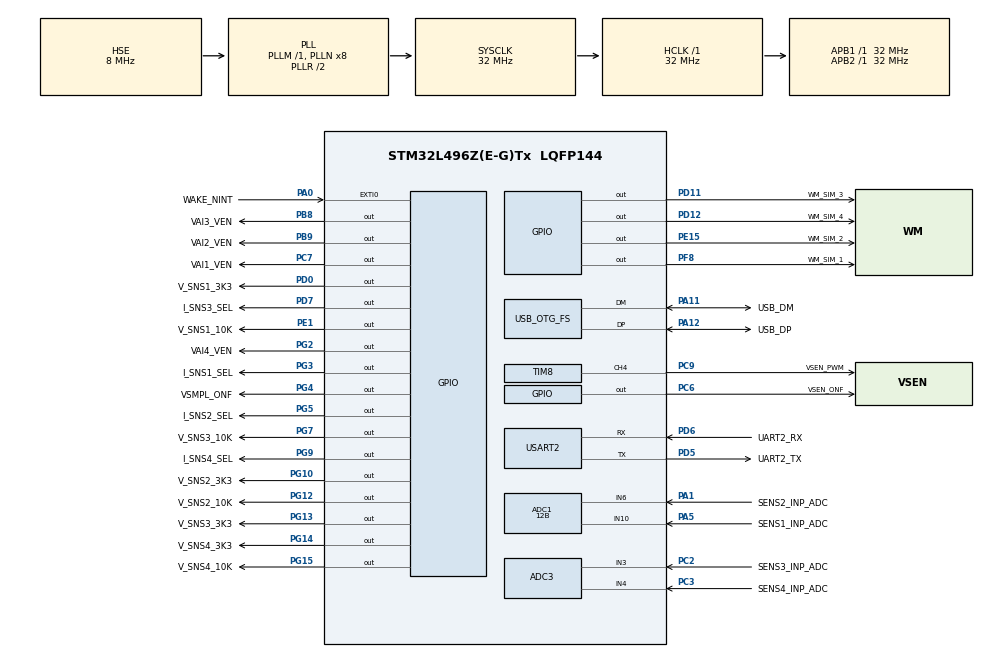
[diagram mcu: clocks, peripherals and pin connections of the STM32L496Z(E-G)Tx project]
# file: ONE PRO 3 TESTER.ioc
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ADC1.Channel-1\#ChannelRegularConversion=ADC_CHANNEL_6
ADC1.Channel-10\#ChannelRegularConversion=ADC_CHANNEL_6
ADC1.Channel-11\#ChannelRegularConversion=ADC_CHANNEL_6
ADC1.Channel-12\#ChannelRegularConversion=ADC_CHANNEL_6
ADC1.Channel-13\#ChannelRegularConversion=ADC_CHANNEL_6
ADC1.Channel-14\#ChannelRegularConversion=ADC_CHANNEL_6
ADC1.Channel-15\#ChannelRegularConversion=ADC_CHANNEL_6
ADC1.Channel-16\#ChannelRegularConversion=ADC_CHANNEL_6
ADC1.Channel-2\#ChannelRegularConversion=ADC_CHANNEL_6
ADC1.Channel-3\#ChannelRegularConversion=ADC_CHANNEL_6
ADC1.Channel-4\#ChannelRegularConversion=ADC_CHANNEL_6
ADC1.Channel-5\#ChannelRegularConversion=ADC_CHANNEL_6
ADC1.Channel-6\#ChannelRegularConversion=ADC_CHANNEL_6
ADC1.Channel-7\#ChannelRegularConversion=ADC_CHANNEL_6
ADC1.Channel-8\#ChannelRegularConversion=ADC_CHANNEL_6
ADC1.Channel-9\#ChannelRegularConversion=ADC_CHANNEL_6
ADC1.ClockPrescaler=ADC_CLOCK_ASYNC_DIV128
ADC1.DMAContinuousRequestsForConfigFile-ADC_Settings=LIMITED
ADC1.DataAlign=ADC_DATAALIGN_RIGHT
ADC1.NbrOfConversion=16
ADC1.NbrOfConversionFlag=1
ADC1.OffsetNumber-1\#ChannelRegularConversion=ADC_OFFSET_NONE
ADC1.OffsetNumber-10\#ChannelRegularConversion=ADC_OFFSET_NONE
ADC1.OffsetNumber-11\#ChannelRegularConversion=ADC_OFFSET_NONE
ADC1.OffsetNumber-12\#ChannelRegularConversion=ADC_OFFSET_NONE
ADC1.OffsetNumber-13\#ChannelRegularConversion=ADC_OFFSET_NONE
ADC1.OffsetNumber-14\#ChannelRegularConversion=ADC_OFFSET_NONE
ADC1.OffsetNumber-15\#ChannelRegularConversion=ADC_OFFSET_NONE
ADC1.OffsetNumber-16\#ChannelRegularConversion=ADC_OFFSET_NONE
ADC1.OffsetNumber-2\#ChannelRegularConversion=ADC_OFFSET_NONE
ADC1.OffsetNumber-3\#ChannelRegularConversion=ADC_OFFSET_NONE
ADC1.OffsetNumber-4\#ChannelRegularConversion=ADC_OFFSET_NONE
ADC1.OffsetNumber-5\#ChannelRegularConversion=ADC_OFFSET_NONE
ADC1.OffsetNumber-6\#ChannelRegularConversion=ADC_OFFSET_NONE
ADC1.OffsetNumber-7\#ChannelRegularConversion=ADC_OFFSET_NONE
ADC1.OffsetNumber-8\#ChannelRegularConversion=ADC_OFFSET_NONE
ADC1.OffsetNumber-9\#ChannelRegularConversion=ADC_OFFSET_NONE
ADC1.Rank-1\#ChannelRegularConversion=1
ADC1.Rank-10\#ChannelRegularConversion=10
ADC1.Rank-11\#ChannelRegularConversion=11
ADC1.Rank-12\#ChannelRegularConversion=12
ADC1.Rank-13\#ChannelRegularConversion=13
ADC1.Rank-14\#ChannelRegularConversion=14
ADC1.Rank-15\#ChannelRegularConversion=15
ADC1.Rank-16\#ChannelRegularConversion=16
ADC1.Rank-2\#ChannelRegularConversion=2
ADC1.Rank-3\#ChannelRegularConversion=3
ADC1.Rank-4\#ChannelRegularConversion=4
ADC1.Rank-5\#ChannelRegularConversion=5
ADC1.Rank-6\#ChannelRegularConversion=6
ADC1.Rank-7\#ChannelRegularConversion=7
ADC1.Rank-8\#ChannelRegularConversion=8
ADC1.Rank-9\#ChannelRegularConversion=9
ADC1.Resolution=ADC_RESOLUTION_12B
ADC1.SamplingTime-1\#ChannelRegularConversion=ADC_SAMPLETIME_2CYCLES_5
ADC1.SamplingTime-10\#ChannelRegularConversion=ADC_SAMPLETIME_2CYCLES_5
ADC1.SamplingTime-11\#ChannelRegularConversion=ADC_SAMPLETIME_2CYCLES_5
ADC1.SamplingTime-12\#ChannelRegularConversion=ADC_SAMPLETIME_2CYCLES_5
ADC1.SamplingTime-13\#ChannelRegularConversion=ADC_SAMPLETIME_2CYCLES_5
ADC1.SamplingTime-14\#ChannelRegularConversion=ADC_SAMPLETIME_2CYCLES_5
ADC1.SamplingTime-15\#ChannelRegularConversion=ADC_SAMPLETIME_2CYCLES_5
ADC1.SamplingTime-16\#ChannelRegularConversion=ADC_SAMPLETIME_2CYCLES_5
ADC1.SamplingTime-2\#ChannelRegularConversion=ADC_SAMPLETIME_2CYCLES_5
ADC1.SamplingTime-3\#ChannelRegularConversion=ADC_SAMPLETIME_2CYCLES_5
ADC1.SamplingTime-4\#ChannelRegularConversion=ADC_SAMPLETIME_2CYCLES_5
ADC1.SamplingTime-5\#ChannelRegularConversion=ADC_SAMPLETIME_2CYCLES_5
ADC1.SamplingTime-6\#ChannelRegularConversion=ADC_SAMPLETIME_2CYCLES_5
ADC1.SamplingTime-7\#ChannelRegularConversion=ADC_SAMPLETIME_2CYCLES_5
ADC1.SamplingTime-8\#ChannelRegularConversion=ADC_SAMPLETIME_2CYCLES_5
ADC1.SamplingTime-9\#ChannelRegularConversion=ADC_SAMPLETIME_2CYCLES_5
ADC1.master=1
ADC3.Channel-10\#ChannelRegularConversion=ADC_CHANNEL_6
ADC3.Channel-11\#ChannelRegularConversion=ADC_CHANNEL_3
ADC3.Channel-12\#ChannelRegularConversion=ADC_CHANNEL_3
ADC3.Channel-13\#ChannelRegularConversion=ADC_CHANNEL_3
ADC3.Channel-14\#ChannelRegularConversion=ADC_CHANNEL_3
ADC3.Channel-15\#ChannelRegularConversion=ADC_CHANNEL_3
ADC3.Channel-16\#ChannelRegularConversion=ADC_CHANNEL_3
ADC3.Channel-17\#ChannelRegularConversion=ADC_CHANNEL_3
ADC3.Channel-18\#ChannelRegularConversion=ADC_CHANNEL_3
ADC3.Channel-19\#ChannelRegularConversion=ADC_CHANNEL_3
ADC3.Channel-20\#ChannelRegularConversion=ADC_CHANNEL_3
ADC3.Channel-21\#ChannelRegularConversion=ADC_CHANNEL_3
ADC3.Channel-22\#ChannelRegularConversion=ADC_CHANNEL_3
ADC3.Channel-23\#ChannelRegularConversion=ADC_CHANNEL_3
ADC3.Channel-24\#ChannelRegularConversion=ADC_CHANNEL_3
ADC3.Channel-25\#ChannelRegularConversion=ADC_CHANNEL_3
ADC3.ClockPrescaler=ADC_CLOCK_ASYNC_DIV128
ADC3.DataAlign=ADC_DATAALIGN_RIGHT
ADC3.NbrOfConversion=16
ADC3.NbrOfConversionFlag=1
ADC3.OffsetNumber-10\#ChannelRegularConversion=ADC_OFFSET_NONE
ADC3.OffsetNumber-11\#ChannelRegularConversion=ADC_OFFSET_NONE
ADC3.OffsetNumber-12\#ChannelRegularConversion=ADC_OFFSET_NONE
ADC3.OffsetNumber-13\#ChannelRegularConversion=ADC_OFFSET_NONE
ADC3.OffsetNumber-14\#ChannelRegularConversion=ADC_OFFSET_NONE
ADC3.OffsetNumber-15\#ChannelRegularConversion=ADC_OFFSET_NONE
ADC3.OffsetNumber-16\#ChannelRegularConversion=ADC_OFFSET_NONE
ADC3.OffsetNumber-17\#ChannelRegularConversion=ADC_OFFSET_NONE
ADC3.OffsetNumber-18\#ChannelRegularConversion=ADC_OFFSET_NONE
ADC3.OffsetNumber-19\#ChannelRegularConversion=ADC_OFFSET_NONE
ADC3.OffsetNumber-20\#ChannelRegularConversion=ADC_OFFSET_NONE
ADC3.OffsetNumber-21\#ChannelRegularConversion=ADC_OFFSET_NONE
ADC3.OffsetNumber-22\#ChannelRegularConversion=ADC_OFFSET_NONE
ADC3.OffsetNumber-23\#ChannelRegularConversion=ADC_OFFSET_NONE
ADC3.OffsetNumber-24\#ChannelRegularConversion=ADC_OFFSET_NONE
ADC3.OffsetNumber-25\#ChannelRegularConversion=ADC_OFFSET_NONE
ADC3.Rank-10\#ChannelRegularConversion=1
ADC3.Rank-11\#ChannelRegularConversion=2
ADC3.Rank-12\#ChannelRegularConversion=3
ADC3.Rank-13\#ChannelRegularConversion=4
ADC3.Rank-14\#ChannelRegularConversion=5
ADC3.Rank-15\#ChannelRegularConversion=6
ADC3.Rank-16\#ChannelRegularConversion=7
ADC3.Rank-17\#ChannelRegularConversion=8
ADC3.Rank-18\#ChannelRegularConversion=9
ADC3.Rank-19\#ChannelRegularConversion=10
ADC3.Rank-20\#ChannelRegularConversion=11
ADC3.Rank-21\#ChannelRegularConversion=12
ADC3.Rank-22\#ChannelRegularConversion=13
ADC3.Rank-23\#ChannelRegularConversion=14
ADC3.Rank-24\#ChannelRegularConversion=15
ADC3.Rank-25\#ChannelRegularConversion=16
ADC3.SamplingTime-10\#ChannelRegularConversion=ADC_SAMPLETIME_2CYCLES_5
ADC3.SamplingTime-11\#ChannelRegularConversion=ADC_SAMPLETIME_2CYCLES_5
ADC3.SamplingTime-12\#ChannelRegularConversion=ADC_SAMPLETIME_2CYCLES_5
ADC3.SamplingTime-13\#ChannelRegularConversion=ADC_SAMPLETIME_2CYCLES_5
ADC3.SamplingTime-14\#ChannelRegularConversion=ADC_SAMPLETIME_2CYCLES_5
ADC3.SamplingTime-15\#ChannelRegularConversion=ADC_SAMPLETIME_2CYCLES_5
ADC3.SamplingTime-16\#ChannelRegularConversion=ADC_SAMPLETIME_2CYCLES_5
ADC3.SamplingTime-17\#ChannelRegularConversion=ADC_SAMPLETIME_2CYCLES_5
ADC3.SamplingTime-18\#ChannelRegularConversion=ADC_SAMPLETIME_2CYCLES_5
ADC3.SamplingTime-19\#ChannelRegularConversion=ADC_SAMPLETIME_2CYCLES_5
ADC3.SamplingTime-20\#ChannelRegularConversion=ADC_SAMPLETIME_2CYCLES_5
ADC3.SamplingTime-21\#ChannelRegularConversion=ADC_SAMPLETIME_2CYCLES_5
ADC3.SamplingTime-22\#ChannelRegularConversion=ADC_SAMPLETIME_2CYCLES_5
ADC3.SamplingTime-23\#ChannelRegularConversion=ADC_SAMPLETIME_2CYCLES_5
ADC3.SamplingTime-24\#ChannelRegularConversion=ADC_SAMPLETIME_2CYCLES_5
ADC3.SamplingTime-25\#ChannelRegularConversion=ADC_SAMPLETIME_2CYCLES_5
Dma.Request0=USART2_RX
Dma.USART2_RX.0.Direction=DMA_PERIPH_TO_MEMORY
Dma.USART2_RX.0.Instance=DMA1_Channel6
Dma.USART2_RX.0.MemDataAlignment=DMA_MDATAALIGN_BYTE
Dma.USART2_RX.0.MemInc=DMA_MINC_ENABLE
Dma.USART2_RX.0.Mode=DMA_CIRCULAR
Dma.USART2_RX.0.PeriphDataAlignment=DMA_PDATAALIGN_BYTE
Dma.USART2_RX.0.PeriphInc=DMA_PINC_DISABLE
Dma.USART2_RX.0.Priority=DMA_PRIORITY_LOW
FREERTOS.Tasks01=defaultTask,24,512,StartDefaultTask,Default,NULL,Dynamic,NULL,NULL
FREERTOS.configMINIMAL_STACK_SIZE=512
FREERTOS.configTOTAL_HEAP_SIZE=16384
Mcu.Family=STM32L4
Mcu.Name=STM32L496Z(E-G)Tx
Mcu.Package=LQFP144
NVIC.DMA1_Channel6_IRQn=true\:5\:0\:false\:false\:true\:true\:false\:true\:true
NVIC.EXTI0_IRQn=true\:5\:0\:false\:false\:true\:true\:true\:true\:true
NVIC.OTG_FS_IRQn=true\:5\:0\:false\:false\:true\:true\:true\:true\:true
NVIC.PriorityGroup=NVIC_PRIORITYGROUP_4
NVIC.USART2_IRQn=true\:5\:0\:false\:false\:true\:true\:true\:true\:true
PA0.GPIO_Label=WAKE_NINT
PA0.Signal=GPXTI0
PA1.GPIO_Label=SENS2_INP_ADC
PA1.Signal=ADCx_IN6
PA11.GPIO_Label=USB_DM
PA11.Mode=Device_Only
PA11.Signal=USB_OTG_FS_DM
PA12.GPIO_Label=USB_DP
PA12.Mode=Device_Only
PA12.Signal=USB_OTG_FS_DP
PA13\ (JTMS/SWDIO).GPIO_Label=JTMS/SWDIO
PA13\ (JTMS/SWDIO).Mode=JTAG_5_pins
PA13\ (JTMS/SWDIO).Signal=SYS_JTMS-SWDIO
PA14\ (JTCK/SWCLK).Mode=JTAG_5_pins
PA14\ (JTCK/SWCLK).Signal=SYS_JTCK-SWCLK
PA15\ (JTDI).Mode=JTAG_5_pins
PA15\ (JTDI).Signal=SYS_JTDI
PA5.GPIO_Label=SENS1_INP_ADC
PA5.Signal=ADCx_IN10
PB3\ (JTDO/TRACESWO).GPIO_Label=JTDO/TRACESWO
PB3\ (JTDO/TRACESWO).Mode=JTAG_5_pins
PB3\ (JTDO/TRACESWO).Signal=SYS_JTDO-SWO
PB4\ (NJTRST).GPIO_Label=NJTRST
PB4\ (NJTRST).Mode=JTAG_5_pins
PB4\ (NJTRST).Signal=SYS_JTRST
PB8.GPIO_Label=VAI3_VEN
PB8.Signal=GPIO_Output
PB9.GPIO_Label=VAI2_VEN
PB9.Signal=GPIO_Output
PC14-OSC32_IN\ (PC14).Mode=LSE-External-Oscillator
PC14-OSC32_IN\ (PC14).Signal=RCC_OSC32_IN
PC15-OSC32_OUT\ (PC15).Mode=LSE-External-Oscillator
PC15-OSC32_OUT\ (PC15).Signal=RCC_OSC32_OUT
PC2.GPIO_Label=SENS3_INP_ADC
PC2.Signal=ADCx_IN3
PC3.GPIO_Label=SENS4_INP_ADC
PC3.Signal=ADCx_IN4
PC6.GPIO_Label=VSEN_ONF
PC6.Signal=GPIO_Output
PC7.GPIO_Label=VAI1_VEN
PC7.Signal=GPIO_Output
PC9.GPIO_Label=VSEN_PWM
PC9.Signal=S_TIM8_CH4
PD0.GPIO_Label=V_SNS1_3K3
PD0.Signal=GPIO_Output
PD11.GPIO_Label=WM_SIM_3
PD11.Signal=GPIO_Output
PD12.GPIO_Label=WM_SIM_4
PD12.Signal=GPIO_Output
PD5.GPIO_Label=UART2_TX
PD5.Mode=Asynchronous
PD5.Signal=USART2_TX
PD6.GPIO_Label=UART2_RX
PD6.GPIO_PuPd=GPIO_PULLUP
PD6.Mode=Asynchronous
PD6.Signal=USART2_RX
PD7.GPIO_Label=I_SNS3_SEL
PD7.Signal=GPIO_Output
PE1.GPIO_Label=V_SNS1_10K
PE1.Signal=GPIO_Output
PE15.GPIO_Label=WM_SIM_2
PE15.Signal=GPIO_Output
PF8.GPIO_Label=WM_SIM_1
PF8.Signal=GPIO_Output
PG10.GPIO_Label=V_SNS2_3K3
PG10.Signal=GPIO_Output
PG12.GPIO_Label=V_SNS2_10K
PG12.Signal=GPIO_Output
PG13.GPIO_Label=V_SNS3_3K3
PG13.Signal=GPIO_Output
PG14.GPIO_Label=V_SNS4_3K3
PG14.Signal=GPIO_Output
PG15.GPIO_Label=V_SNS4_10K
PG15.Signal=GPIO_Output
PG2.GPIO_Label=VAI4_VEN
PG2.Signal=GPIO_Output
PG3.GPIO_Label=I_SNS1_SEL
PG3.Signal=GPIO_Output
PG4.GPIO_Label=VSMPL_ONF
PG4.Signal=GPIO_Output
PG5.GPIO_Label=I_SNS2_SEL
PG5.Signal=GPIO_Output
PG7.GPIO_Label=V_SNS3_10K
PG7.Signal=GPIO_Output
PG9.GPIO_Label=I_SNS4_SEL
PG9.Signal=GPIO_Output
PH0-OSC_IN\ (PH0).Mode=HSE-External-Oscillator
PH0-OSC_IN\ (PH0).Signal=RCC_OSC_IN
PH1-OSC_OUT\ (PH1).Mode=HSE-External-Oscillator
PH1-OSC_OUT\ (PH1).Signal=RCC_OSC_OUT
ProjectManager.HeapSize=0x200
ProjectManager.StackSize=0x400
ProjectManager.TargetToolchain=STM32CubeIDE
RCC.ADCCLockSelection=RCC_ADCCLKSOURCE_PLLSAI2
RCC.ADCFreq_Value=8000000
RCC.AHBFreq_Value=32000000
RCC.APB1Freq_Value=32000000
RCC.APB1TimFreq_Value=32000000
RCC.APB2Freq_Value=32000000
RCC.APB2TimFreq_Value=32000000
RCC.CortexFreq_Value=32000000
RCC.FLatency-AdvancedSettings=FLASH_LATENCY_1
RCC.HCLKFreq_Value=32000000
RCC.HSE_VALUE=8000000
RCC.HSI48_VALUE=48000000
RCC.HSI_VALUE=16000000
RCC.LSE_Drive_Capability=RCC_LSEDRIVE_MEDIUMLOW
RCC.MSI_VALUE=4000000
RCC.PLLSAI1N=12
RCC.PLLSAI2R=RCC_PLLR_DIV8
RCC.PLLSourceVirtual=RCC_PLLSOURCE_HSE
RCC.RTCClockSelection=RCC_RTCCLKSOURCE_LSE
RCC.SYSCLKFreq_VALUE=32000000
RCC.SYSCLKSource=RCC_SYSCLKSOURCE_PLLCLK
RCC.USBFreq_Value=48000000
RCC.VCOOutputFreq_Value=64000000
RTC.Date=12
RTC.Month=RTC_MONTH_MAY
RTC.Seconds=1
RTC.StoreOperation=RTC_STOREOPERATION_SET
RTC.WeekDay=RTC_WEEKDAY_SUNDAY
RTC.Year=24
SH.ADCx_IN10.0=ADC1_IN10,IN10-Single-Ended
SH.ADCx_IN3.0=ADC3_IN3,IN3-Single-Ended
SH.ADCx_IN4.0=ADC3_IN4,IN4-Single-Ended
SH.ADCx_IN6.0=ADC1_IN6,IN6-Single-Ended
SH.S_TIM8_CH4.0=TIM8_CH4,PWM Generation4 CH4
TIM3.AutoReloadPreload=TIM_AUTORELOAD_PRELOAD_ENABLE
TIM3.ClockDivision=TIM_CLOCKDIVISION_DIV1
TIM3.Prescaler=0
TIM7.AutoReloadPreload=TIM_AUTORELOAD_PRELOAD_ENABLE
TIM8.AutoReloadPreload=TIM_AUTORELOAD_PRELOAD_ENABLE
TIM8.Channel-PWM\ Generation4\ CH4=TIM_CHANNEL_4
USART2.VirtualMode-Asynchronous=VM_ASYNC
USB_DEVICE.CLASS_NAME_FS=CDC
USB_DEVICE.VirtualMode=Cdc
USB_DEVICE.VirtualModeFS=Cdc_FS
USB_OTG_FS.VirtualMode=Device_Only
VP_FREERTOS_VS_CMSIS_V2.Mode=CMSIS_V2
VP_RTC_VS_RTC_Activate.Mode=RTC_Enabled
VP_RTC_VS_RTC_Calendar.Mode=RTC_Calendar
VP_TIM3_VS_ClockSourceINT.Mode=Internal
VP_TIM7_VS_ClockSourceINT.Mode=Enable_Timer
VP_TIM8_VS_ClockSourceINT.Mode=Internal
VP_USB_DEVICE_VS_USB_DEVICE_CDC_FS.Mode=CDC_FS
board=custom

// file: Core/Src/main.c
/* USER CODE BEGIN Header */
/**
  ******************************************************************************
  * @file           : main.c
  * @brief          : Main program body
  ******************************************************************************
  * @attention
  *
  * Copyright (c) 2026 STMicroelectronics.
  * All rights reserved.
  *
  * This software is licensed under terms that can be found in the LICENSE file
  * in the root directory of this software component.
  * If no LICENSE file comes with this software, it is provided AS-IS.
  *
  ******************************************************************************
  */
/* USER CODE END Header */
#include "main.h"
#include "cmsis_os.h"
#include "adc.h"
#include "dma.h"
#include "rtc.h"
#include "tim.h"
#include "usart.h"
#include "usb_device.h"
#include "gpio.h"

void SystemClock_Config(void);
void PeriphCommonClock_Config(void);
void MX_FREERTOS_Init(void);

int main(void)
{

  /* MCU Configuration--------------------------------------------------------*/

  /* Reset of all peripherals, Initializes the Flash interface and the Systick. */
  HAL_Init();

  /* Configure the system clock */
  SystemClock_Config();

  /* Configure the peripherals common clocks */
  PeriphCommonClock_Config();

  /* Initialize all configured peripherals */
  MX_GPIO_Init();
  MX_DMA_Init();
  MX_TIM3_Init();
  MX_TIM8_Init();
  MX_ADC1_Init();
  MX_USART2_UART_Init();
  MX_ADC3_Init();
  MX_TIM7_Init();
  MX_RTC_Init();

  /* Init scheduler */
  osKernelInitialize();  /* Call init function for freertos objects (in cmsis_os2.c) */
  MX_FREERTOS_Init();

  /* Start scheduler */
  osKernelStart();

  /* We should never get here as control is now taken by the scheduler */

  /* Infinite loop */
  while (1)
  {

  }
}

void SystemClock_Config(void)
{
  RCC_OscInitTypeDef RCC_OscInitStruct = {0};
  RCC_ClkInitTypeDef RCC_ClkInitStruct = {0};

  /** Configure the main internal regulator output voltage
  */
  if (HAL_PWREx_ControlVoltageScaling(PWR_REGULATOR_VOLTAGE_SCALE1) != HAL_OK)
  {
    Error_Handler();
  }

  /** Configure LSE Drive Capability
  */
  HAL_PWR_EnableBkUpAccess();
  __HAL_RCC_LSEDRIVE_CONFIG(RCC_LSEDRIVE_MEDIUMLOW);

  /** Initializes the RCC Oscillators according to the specified parameters
  * in the RCC_OscInitTypeDef structure.
  */
  RCC_OscInitStruct.OscillatorType = RCC_OSCILLATORTYPE_HSE|RCC_OSCILLATORTYPE_LSE;
  RCC_OscInitStruct.HSEState = RCC_HSE_ON;
  RCC_OscInitStruct.LSEState = RCC_LSE_ON;
  RCC_OscInitStruct.PLL.PLLState = RCC_PLL_ON;
  RCC_OscInitStruct.PLL.PLLSource = RCC_PLLSOURCE_HSE;
  RCC_OscInitStruct.PLL.PLLM = 1;
  RCC_OscInitStruct.PLL.PLLN = 8;
  RCC_OscInitStruct.PLL.PLLP = RCC_PLLP_DIV2;
  RCC_OscInitStruct.PLL.PLLQ = RCC_PLLQ_DIV2;
  RCC_OscInitStruct.PLL.PLLR = RCC_PLLR_DIV2;
  if (HAL_RCC_OscConfig(&RCC_OscInitStruct) != HAL_OK)
  {
    Error_Handler();
  }

  /** Initializes the CPU, AHB and APB buses clocks
  */
  RCC_ClkInitStruct.ClockType = RCC_CLOCKTYPE_HCLK|RCC_CLOCKTYPE_SYSCLK
                              |RCC_CLOCKTYPE_PCLK1|RCC_CLOCKTYPE_PCLK2;
  RCC_ClkInitStruct.SYSCLKSource = RCC_SYSCLKSOURCE_PLLCLK;
  RCC_ClkInitStruct.AHBCLKDivider = RCC_SYSCLK_DIV1;
  RCC_ClkInitStruct.APB1CLKDivider = RCC_HCLK_DIV1;
  RCC_ClkInitStruct.APB2CLKDivider = RCC_HCLK_DIV1;

  if (HAL_RCC_ClockConfig(&RCC_ClkInitStruct, FLASH_LATENCY_1) != HAL_OK)
  {
    Error_Handler();
  }
}

void PeriphCommonClock_Config(void)
{
  RCC_PeriphCLKInitTypeDef PeriphClkInit = {0};

  /** Initializes the peripherals clock
  */
  PeriphClkInit.PeriphClockSelection = RCC_PERIPHCLK_ADC;
  PeriphClkInit.AdcClockSelection = RCC_ADCCLKSOURCE_PLLSAI2;
  PeriphClkInit.PLLSAI2.PLLSAI2Source = RCC_PLLSOURCE_HSE;
  PeriphClkInit.PLLSAI2.PLLSAI2M = 1;
  PeriphClkInit.PLLSAI2.PLLSAI2N = 8;
  PeriphClkInit.PLLSAI2.PLLSAI2P = RCC_PLLP_DIV2;
  PeriphClkInit.PLLSAI2.PLLSAI2R = RCC_PLLR_DIV8;
  PeriphClkInit.PLLSAI2.PLLSAI2ClockOut = RCC_PLLSAI2_ADC2CLK;
  if (HAL_RCCEx_PeriphCLKConfig(&PeriphClkInit) != HAL_OK)
  {
    Error_Handler();
  }
}

void Error_Handler(void)
{
  __disable_irq();
  while (1)
  {
  }
}

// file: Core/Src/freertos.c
/* USER CODE BEGIN Header */
/**
  ******************************************************************************
  * File Name          : freertos.c
  * Description        : Code for freertos applications
  ******************************************************************************
  * @attention
  *
  * Copyright (c) 2026 STMicroelectronics.
  * All rights reserved.
  *
  * This software is licensed under terms that can be found in the LICENSE file
  * in the root directory of this software component.
  * If no LICENSE file comes with this software, it is provided AS-IS.
  *
  ******************************************************************************
  */
/* USER CODE END Header */

#include "FreeRTOS.h"
#include "task.h"
#include "main.h"
#include "cmsis_os.h"

/* USER CODE BEGIN Includes */
#include "../../Application/appProxy.h"

/* USER CODE END Includes */

/* Definitions for defaultTask */
osThreadId_t defaultTaskHandle;
const osThreadAttr_t defaultTask_attributes = {
  .name = "defaultTask",
  .stack_size = 512 * 4,
  .priority = (osPriority_t) osPriorityNormal,
};

void StartDefaultTask(void *argument);

void MX_FREERTOS_Init(void); /* (MISRA C 2004 rule 8.1) */

void MX_FREERTOS_Init(void) {

  /* Create the thread(s) */
  /* creation of defaultTask */
  defaultTaskHandle = osThreadNew(StartDefaultTask, NULL, &defaultTask_attributes);

}

void StartDefaultTask(void *argument)
{
  /* USER CODE BEGIN StartDefaultTask */

  /* Infinite loop */
	runAppTask();
  /* USER CODE END StartDefaultTask */
}
